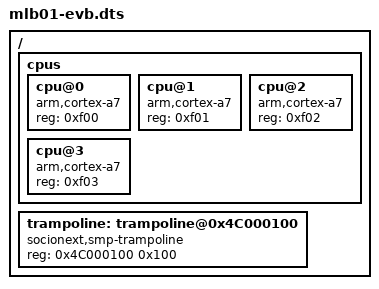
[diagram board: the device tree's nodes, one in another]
/* Socionext SC2000A (MLB01) Evaluation Board without RTOS */
/dts-v1/;
#include "mlb01-evb.dtsi"

/ {
	cpus {
		cpu@0 {
			device_type = "cpu";
			compatible = "arm,cortex-a7";
			reg = <0xf00>;
		};
		cpu@1 {
			device_type = "cpu";
			compatible = "arm,cortex-a7";
			reg = <0xf01>;
		};

		cpu@2 {
			device_type = "cpu";
			compatible = "arm,cortex-a7";
			reg = <0xf02>;
		};
		cpu@3 {
			device_type = "cpu";
			compatible = "arm,cortex-a7";
			reg = <0xf03>;
		};

	};
	trampoline: trampoline@0x4C000100 {
		compatible = "socionext,smp-trampoline";
		reg = <0x4C000100 0x100>;
	};

};
